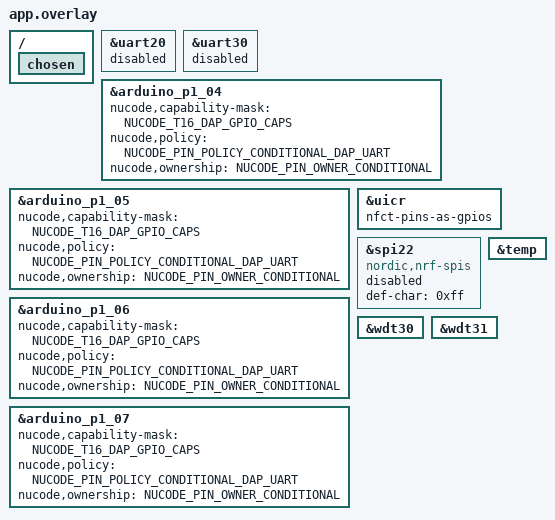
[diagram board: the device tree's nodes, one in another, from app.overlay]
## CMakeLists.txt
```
cmake_minimum_required(VERSION 3.20.0)
find_package(Zephyr REQUIRED HINTS $ENV{ZEPHYR_BASE})
project(t16_peripheral_profile_contract LANGUAGES C CXX)

target_include_directories(
    app
    PRIVATE
        ${CMAKE_CURRENT_SOURCE_DIR}/../../../libraries/NUCODE_Peripheral_Fabric/src
)
target_sources(app PRIVATE src/main.cpp)
```

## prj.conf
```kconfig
CONFIG_CPP=y
CONFIG_STD_CPP17=y
CONFIG_CPP_EXCEPTIONS=n
CONFIG_CPP_RTTI=n

CONFIG_CONSOLE=n
CONFIG_SERIAL=n
CONFIG_LOG=n
CONFIG_UART_CONSOLE=n
CONFIG_ADC=n
CONFIG_PWM=n
CONFIG_I2S=n

CONFIG_NUCODE_ARDUINO_CORE=y
CONFIG_NUCODE_ARDUINO_RUNTIME=y
CONFIG_NUCODE_ARDUINO_API=y
CONFIG_NUCODE_ARDUINO_IO_OWNERSHIP=y
CONFIG_NUCODE_ARDUINO_IO_RESOURCE_SLOTS=128
CONFIG_NUCODE_ARDUINO_GPIO=y
CONFIG_NUCODE_ARDUINO_CONNECTOR_GPIO=y
CONFIG_NUCODE_ARDUINO_DAP_UART_GPIO_PINS=y
CONFIG_NUCODE_ARDUINO_INTERRUPTS=n
CONFIG_NUCODE_ARDUINO_TIME=y
CONFIG_NUCODE_ARDUINO_SERIAL=n
CONFIG_NUCODE_ARDUINO_SERIAL1=n
CONFIG_NUCODE_ARDUINO_WIRE=n
CONFIG_NUCODE_ARDUINO_SPI=n
CONFIG_NUCODE_ARDUINO_ADC=n
CONFIG_NUCODE_ARDUINO_PWM=n

CONFIG_NUCODE_ARDUINO_SERIAL_FABRIC=y
CONFIG_NUCODE_ARDUINO_SERIAL_FABRIC_UARTE=y
CONFIG_NUCODE_ARDUINO_SERIAL_FABRIC_SPIM=y
CONFIG_NUCODE_ARDUINO_SERIAL_FABRIC_SPIS=y
CONFIG_NUCODE_ARDUINO_SERIAL_FABRIC_TWIM=y
CONFIG_NUCODE_ARDUINO_SERIAL_FABRIC_TWIS=y
CONFIG_NUCODE_ARDUINO_ANALOG_FABRIC=y
CONFIG_NUCODE_ARDUINO_EVENT_FABRIC=y
CONFIG_NUCODE_ARDUINO_STREAM_FABRIC=y
CONFIG_NUCODE_ARDUINO_SYSTEM_FABRIC=y

CONFIG_NRF_SYS_EVENT=y
CONFIG_NRF_SYS_EVENT_IRQ_LATENCY=n
CONFIG_USE_DT_CODE_PARTITION=y
CONFIG_MAIN_STACK_SIZE=8192
```

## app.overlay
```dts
/**
 * @file app.overlay
 * @brief T16 설치 profile과 동일한 직접 Peripheral Fabric route를 검증합니다.
 *
 * SPDX-License-Identifier: MIT
 */

#include <nucode/nu54dk-arduino-connectors.dtsi>
#include <nucode/nu54dk-arduino-pins.dtsi>
#include <nucode/nu54dk-arduino-runtime.dtsi>

/ {
    chosen {
        /delete-property/ zephyr,console;
        /delete-property/ zephyr,shell-uart;
        /delete-property/ zephyr,uart-mcumgr;
        /delete-property/ zephyr,bt-mon-uart;
        /delete-property/ zephyr,bt-c2h-uart;
    };
};

&uart20 {
    status = "disabled";
};

&uart30 {
    status = "disabled";
};

#define NUCODE_T16_DAP_GPIO_CAPS                                                                    \
    (NUCODE_PIN_CAP_INPUT | NUCODE_PIN_CAP_OUTPUT | NUCODE_PIN_CAP_ANALOG |                         \
     NUCODE_PIN_CAP_OPEN_DRAIN | NUCODE_PIN_CAP_INTERRUPT)

&arduino_p1_04 {
    nucode,capability-mask = <NUCODE_T16_DAP_GPIO_CAPS>;
    nucode,policy = <NUCODE_PIN_POLICY_CONDITIONAL_DAP_UART>;
    nucode,ownership = <NUCODE_PIN_OWNER_CONDITIONAL>;
};

&arduino_p1_05 {
    nucode,capability-mask = <NUCODE_T16_DAP_GPIO_CAPS>;
    nucode,policy = <NUCODE_PIN_POLICY_CONDITIONAL_DAP_UART>;
    nucode,ownership = <NUCODE_PIN_OWNER_CONDITIONAL>;
};

&arduino_p1_06 {
    nucode,capability-mask = <NUCODE_T16_DAP_GPIO_CAPS>;
    nucode,policy = <NUCODE_PIN_POLICY_CONDITIONAL_DAP_UART>;
    nucode,ownership = <NUCODE_PIN_OWNER_CONDITIONAL>;
};

&arduino_p1_07 {
    nucode,capability-mask = <NUCODE_T16_DAP_GPIO_CAPS>;
    nucode,policy = <NUCODE_PIN_POLICY_CONDITIONAL_DAP_UART>;
    nucode,ownership = <NUCODE_PIN_OWNER_CONDITIONAL>;
};

#undef NUCODE_T16_DAP_GPIO_CAPS

&uicr {
    nfct-pins-as-gpios;
};

&spi22 {
    compatible = "nordic,nrf-spis";
    /delete-property/ rx-delay-supported;
    /delete-property/ rx-delay;
    def-char = <0xff>;
    status = "disabled";
};

&temp {
    status = "okay";
};

&wdt30 {
    status = "okay";
};

&wdt31 {
    status = "okay";
};
```

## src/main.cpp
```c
/**
 * @file main.cpp
 * @brief T16 설치 facade와 지원 Fabric factory가 한 image에 링크되는지 검증합니다.
 *
 * SPDX-License-Identifier: MIT
 */

#include <NUCODE_Peripheral_Fabric.h>

namespace
{
    volatile bool fabric_ready = false;
}

void setup()
{
    using namespace nucode::arduino;
    using namespace nucode::peripheral;

    fabric_ready = serialFabric().uarte(0U) != nullptr && serialFabric().spim(0U) != nullptr &&
                   serialFabric().spis(0U) != nullptr && serialFabric().twim(20U) != nullptr &&
                   serialFabric().twis(20U) != nullptr && analogFabric().pwm(20U) != nullptr &&
                   eventFabric().timer(20U) != nullptr && eventFabric().egu(20U) != nullptr &&
                   eventFabric().gpiote(20U) != nullptr && eventFabric().dppi(20U) != nullptr &&
                   eventFabric().ppib(20U) != nullptr && streamFabric().pdm(20U) != nullptr &&
                   streamFabric().i2s(20U) != nullptr && streamFabric().qdec(20U) != nullptr &&
                   streamFabric().qdec(21U) != nullptr && systemFabric().watchdog(30U) != nullptr &&
                   peripheralInventorySize() == 75U && isSupported(capabilities.serial) &&
                   isSupported(capabilities.analog) && isSupported(capabilities.event) &&
                   isSupported(capabilities.pdm) && isSupported(capabilities.i2s) &&
                   isSupported(capabilities.qdec) && isSupported(capabilities.system);
}

void loop()
{
    delay(fabric_ready ? 1000U : 100U);
}
```
